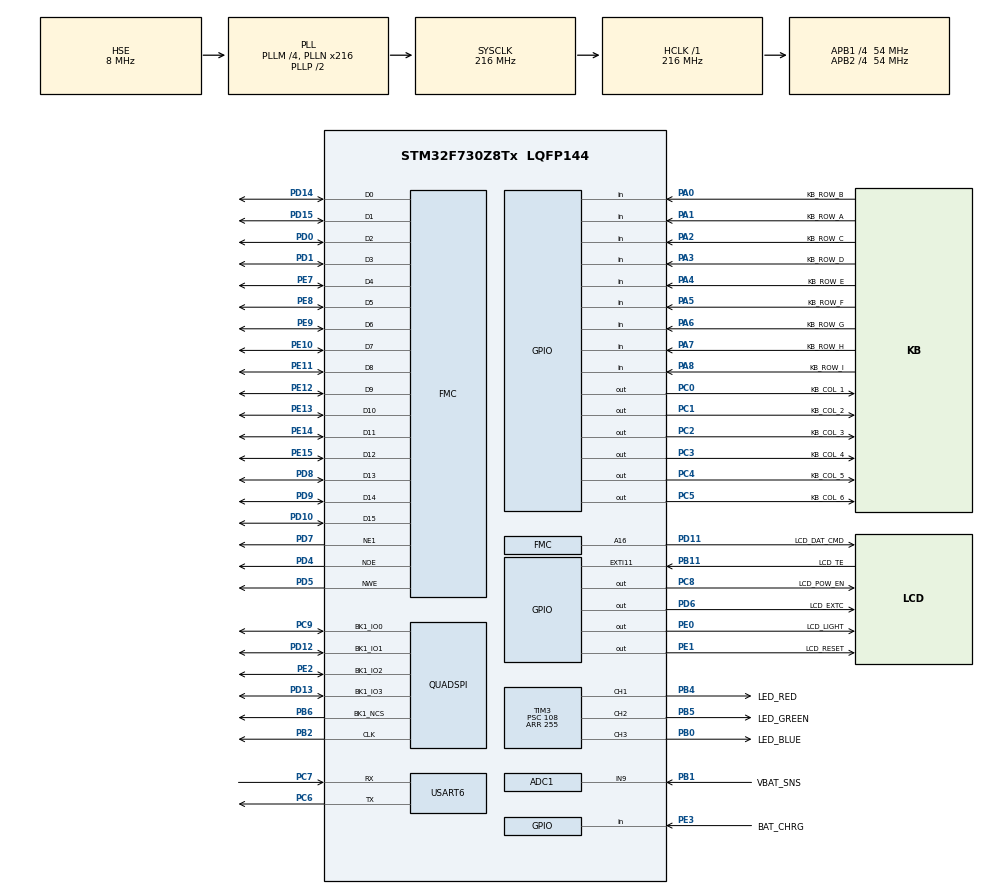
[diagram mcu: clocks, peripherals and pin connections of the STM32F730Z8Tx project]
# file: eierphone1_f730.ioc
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ADC1.Channel-0\#ChannelRegularConversion=ADC_CHANNEL_9
ADC1.NbrOfConversionFlag=1
ADC1.Rank-0\#ChannelRegularConversion=1
ADC1.SamplingTime-0\#ChannelRegularConversion=ADC_SAMPLETIME_3CYCLES
ADC1.master=1
CORTEX_M7.AccessPermission_Spec=MPU_REGION_FULL_ACCESS
CORTEX_M7.CPU_DCache=Disabled
CORTEX_M7.CPU_ICache=Enabled
CORTEX_M7.FlashInterface=TCM_Enabled
CORTEX_M7.PREFETCH_ENABLE=1
CORTEX_M7.default_mode_Activation=1
Dma.MEMTOMEM.0.Direction=DMA_MEMORY_TO_MEMORY
Dma.MEMTOMEM.0.FIFOMode=DMA_FIFOMODE_ENABLE
Dma.MEMTOMEM.0.FIFOThreshold=DMA_FIFO_THRESHOLD_1QUARTERFULL
Dma.MEMTOMEM.0.Instance=DMA2_Stream1
Dma.MEMTOMEM.0.MemBurst=DMA_MBURST_SINGLE
Dma.MEMTOMEM.0.MemDataAlignment=DMA_MDATAALIGN_HALFWORD
Dma.MEMTOMEM.0.MemInc=DMA_MINC_DISABLE
Dma.MEMTOMEM.0.Mode=DMA_NORMAL
Dma.MEMTOMEM.0.PeriphBurst=DMA_PBURST_SINGLE
Dma.MEMTOMEM.0.PeriphDataAlignment=DMA_PDATAALIGN_WORD
Dma.MEMTOMEM.0.PeriphInc=DMA_PINC_ENABLE
Dma.MEMTOMEM.0.Priority=DMA_PRIORITY_HIGH
Dma.Request0=MEMTOMEM
FMC.AddressSetupTime1=2
FMC.BusTurnAroundDuration1=2
FMC.DataSetupTime1=8
FMC.WriteFifo1=FMC_WRITE_FIFO_DISABLE
FMC.WriteFifo2=FMC_WRITE_FIFO_DISABLE
FMC.WriteFifo3=FMC_WRITE_FIFO_DISABLE
FMC.WriteFifo4=FMC_WRITE_FIFO_DISABLE
FREERTOS.INCLUDE_pcTaskGetTaskName=1
FREERTOS.Tasks01=defaultTask,24,128,StartDefaultTask,Default,NULL,Dynamic,NULL,NULL;coreTask,24,512,core,As external,NULL,Dynamic,NULL,NULL
FREERTOS.configCHECK_FOR_STACK_OVERFLOW=2
FREERTOS.configENABLE_FPU=1
FREERTOS.configGENERATE_RUN_TIME_STATS=1
FREERTOS.configRECORD_STACK_HIGH_ADDRESS=1
FREERTOS.configTOTAL_HEAP_SIZE=65536
FREERTOS.configUSE_MALLOC_FAILED_HOOK=1
FREERTOS.configUSE_NEWLIB_REENTRANT=1
Mcu.Family=STM32F7
Mcu.Name=STM32F730Z8Tx
Mcu.Package=LQFP144
NVIC.DMA2_Stream1_IRQn=true\:5\:0\:false\:false\:true\:true\:true\:true\:true
NVIC.EXTI15_10_IRQn=true\:5\:0\:false\:false\:true\:true\:true\:true\:true
NVIC.PriorityGroup=NVIC_PRIORITYGROUP_4
NVIC.QUADSPI_IRQn=true\:5\:0\:false\:false\:true\:true\:true\:true\:true
NVIC.TIM1_UP_TIM10_IRQn=true\:15\:0\:false\:false\:true\:false\:false\:true\:true
NVIC.TIM6_DAC_IRQn=true\:5\:0\:false\:false\:true\:true\:true\:true\:true
NVIC.TimeBase=TIM1_UP_TIM10_IRQn
NVIC.TimeBaseIP=TIM1
PA0-WKUP.GPIO_Label=KB_ROW_B
PA0-WKUP.GPIO_Mode=GPIO_MODE_INPUT
PA0-WKUP.GPIO_PuPd=GPIO_PULLUP
PA0-WKUP.Signal=GPIO_Input
PA1.GPIO_Label=KB_ROW_A
PA1.GPIO_Mode=GPIO_MODE_INPUT
PA1.GPIO_PuPd=GPIO_PULLUP
PA1.Signal=GPIO_Input
PA13.Mode=Serial_Wire
PA13.Signal=SYS_JTMS-SWDIO
PA14.Mode=Serial_Wire
PA14.Signal=SYS_JTCK-SWCLK
PA2.GPIO_Label=KB_ROW_C
PA2.GPIO_Mode=GPIO_MODE_INPUT
PA2.GPIO_PuPd=GPIO_PULLUP
PA2.Signal=GPIO_Input
PA3.GPIO_Label=KB_ROW_D
PA3.GPIO_Mode=GPIO_MODE_INPUT
PA3.GPIO_PuPd=GPIO_PULLUP
PA3.Signal=GPIO_Input
PA4.GPIO_Label=KB_ROW_E
PA4.GPIO_Mode=GPIO_MODE_INPUT
PA4.GPIO_PuPd=GPIO_PULLUP
PA4.Signal=GPIO_Input
PA5.GPIO_Label=KB_ROW_F
PA5.GPIO_Mode=GPIO_MODE_INPUT
PA5.GPIO_PuPd=GPIO_PULLUP
PA5.Signal=GPIO_Input
PA6.GPIO_Label=KB_ROW_G
PA6.GPIO_Mode=GPIO_MODE_INPUT
PA6.GPIO_PuPd=GPIO_PULLUP
PA6.Signal=GPIO_Input
PA7.GPIO_Label=KB_ROW_H
PA7.GPIO_Mode=GPIO_MODE_INPUT
PA7.GPIO_PuPd=GPIO_PULLUP
PA7.Signal=GPIO_Input
PA8.GPIO_Label=KB_ROW_I
PA8.GPIO_Mode=GPIO_MODE_INPUT
PA8.GPIO_PuPd=GPIO_PULLUP
PA8.Signal=GPIO_Input
PB0.GPIO_Label=LED_BLUE
PB0.Signal=S_TIM3_CH3
PB1.GPIO_Label=VBAT_SNS
PB1.Signal=ADCx_IN9
PB11.GPIO_Label=LCD_TE
PB11.GPIO_ModeDefaultEXTI=GPIO_MODE_IT_RISING
PB11.Signal=GPXTI11
PB2.Mode=Single Bank 1
PB2.Signal=QUADSPI_CLK
PB3.Signal=SYS_JTDO-SWO
PB4.GPIO_Label=LED_RED
PB4.Signal=S_TIM3_CH1
PB5.GPIO_Label=LED_GREEN
PB5.Signal=S_TIM3_CH2
PB6.Mode=Single Bank 1
PB6.Signal=QUADSPI_BK1_NCS
PC0.GPIO_Label=KB_COL_1
PC0.GPIO_ModeDefaultOutputPP=GPIO_MODE_OUTPUT_OD
PC0.GPIO_PuPd=GPIO_PULLUP
PC0.GPIO_Speed=GPIO_SPEED_FREQ_LOW
PC0.PinState=GPIO_PIN_SET
PC0.Signal=GPIO_Output
PC1.GPIO_Label=KB_COL_2
PC1.GPIO_ModeDefaultOutputPP=GPIO_MODE_OUTPUT_OD
PC1.GPIO_PuPd=GPIO_PULLUP
PC1.GPIO_Speed=GPIO_SPEED_FREQ_LOW
PC1.PinState=GPIO_PIN_SET
PC1.Signal=GPIO_Output
PC2.GPIO_Label=KB_COL_3
PC2.GPIO_ModeDefaultOutputPP=GPIO_MODE_OUTPUT_OD
PC2.GPIO_PuPd=GPIO_PULLUP
PC2.GPIO_Speed=GPIO_SPEED_FREQ_LOW
PC2.PinState=GPIO_PIN_SET
PC2.Signal=GPIO_Output
PC3.GPIO_Label=KB_COL_4
PC3.GPIO_ModeDefaultOutputPP=GPIO_MODE_OUTPUT_OD
PC3.GPIO_PuPd=GPIO_PULLUP
PC3.GPIO_Speed=GPIO_SPEED_FREQ_LOW
PC3.PinState=GPIO_PIN_SET
PC3.Signal=GPIO_Output
PC4.GPIO_Label=KB_COL_5
PC4.GPIO_ModeDefaultOutputPP=GPIO_MODE_OUTPUT_OD
PC4.GPIO_PuPd=GPIO_PULLUP
PC4.GPIO_Speed=GPIO_SPEED_FREQ_LOW
PC4.PinState=GPIO_PIN_SET
PC4.Signal=GPIO_Output
PC5.GPIO_Label=KB_COL_6
PC5.GPIO_ModeDefaultOutputPP=GPIO_MODE_OUTPUT_OD
PC5.GPIO_PuPd=GPIO_PULLUP
PC5.GPIO_Speed=GPIO_SPEED_FREQ_LOW
PC5.PinState=GPIO_PIN_SET
PC5.Signal=GPIO_Output
PC6.Mode=Asynchronous
PC6.Signal=USART6_TX
PC7.Mode=Asynchronous
PC7.Signal=USART6_RX
PC8.GPIO_Label=LCD_POW_EN
PC8.Signal=GPIO_Output
PC9.GPIO_PuPd=GPIO_PULLUP
PC9.Mode=Single Bank 1
PC9.Signal=QUADSPI_BK1_IO0
PD0.GPIO_Speed_High_Default=GPIO_SPEED_FREQ_HIGH
PD0.Signal=FMC_D2_DA2
PD1.GPIO_Speed_High_Default=GPIO_SPEED_FREQ_HIGH
PD1.Signal=FMC_D3_DA3
PD10.GPIO_Speed_High_Default=GPIO_SPEED_FREQ_HIGH
PD10.Signal=FMC_D15_DA15
PD11.GPIO_Label=LCD_DAT_CMD
PD11.GPIO_Speed_High_Default=GPIO_SPEED_FREQ_HIGH
PD11.Signal=FMC_A16_CLE
PD12.GPIO_PuPd=GPIO_PULLUP
PD12.Mode=Single Bank 1
PD12.Signal=QUADSPI_BK1_IO1
PD13.GPIO_PuPd=GPIO_PULLUP
PD13.Mode=Single Bank 1
PD13.Signal=QUADSPI_BK1_IO3
PD14.GPIO_Speed_High_Default=GPIO_SPEED_FREQ_HIGH
PD14.Signal=FMC_D0_DA0
PD15.GPIO_Speed_High_Default=GPIO_SPEED_FREQ_HIGH
PD15.Signal=FMC_D1_DA1
PD4.GPIO_Speed_High_Default=GPIO_SPEED_FREQ_HIGH
PD4.Signal=FMC_NOE
PD5.GPIO_Speed_High_Default=GPIO_SPEED_FREQ_HIGH
PD5.Signal=FMC_NWE
PD6.GPIO_Label=LCD_EXTC
PD6.Signal=GPIO_Output
PD7.GPIO_Speed_High_Default=GPIO_SPEED_FREQ_HIGH
PD7.Mode=NorPsramChipSelect1_1
PD7.Signal=FMC_NE1
PD8.GPIO_Speed_High_Default=GPIO_SPEED_FREQ_HIGH
PD8.Signal=FMC_D13_DA13
PD9.GPIO_Speed_High_Default=GPIO_SPEED_FREQ_HIGH
PD9.Signal=FMC_D14_DA14
PE0.GPIO_Label=LCD_LIGHT
PE0.GPIO_Speed=GPIO_SPEED_FREQ_HIGH
PE0.Signal=GPIO_Output
PE1.GPIO_Label=LCD_RESET
PE1.Signal=GPIO_Output
PE10.GPIO_Speed_High_Default=GPIO_SPEED_FREQ_HIGH
PE10.Signal=FMC_D7_DA7
PE11.GPIO_Speed_High_Default=GPIO_SPEED_FREQ_HIGH
PE11.Signal=FMC_D8_DA8
PE12.GPIO_Speed_High_Default=GPIO_SPEED_FREQ_HIGH
PE12.Signal=FMC_D9_DA9
PE13.GPIO_Speed_High_Default=GPIO_SPEED_FREQ_HIGH
PE13.Signal=FMC_D10_DA10
PE14.GPIO_Speed_High_Default=GPIO_SPEED_FREQ_HIGH
PE14.Signal=FMC_D11_DA11
PE15.GPIO_Speed_High_Default=GPIO_SPEED_FREQ_HIGH
PE15.Signal=FMC_D12_DA12
PE2.GPIO_PuPd=GPIO_PULLUP
PE2.Mode=Single Bank 1
PE2.Signal=QUADSPI_BK1_IO2
PE3.GPIO_Label=BAT_CHRG
PE3.GPIO_PuPd=GPIO_PULLUP
PE3.Signal=GPIO_Input
PE7.GPIO_Speed_High_Default=GPIO_SPEED_FREQ_HIGH
PE7.Signal=FMC_D4_DA4
PE8.GPIO_Speed_High_Default=GPIO_SPEED_FREQ_HIGH
PE8.Signal=FMC_D5_DA5
PE9.GPIO_Speed_High_Default=GPIO_SPEED_FREQ_HIGH
PE9.Signal=FMC_D6_DA6
PH0-OSC_IN.Mode=HSE-External-Oscillator
PH0-OSC_IN.Signal=RCC_OSC_IN
PH1-OSC_OUT.Mode=HSE-External-Oscillator
PH1-OSC_OUT.Signal=RCC_OSC_OUT
ProjectManager.HeapSize=0x200
ProjectManager.StackSize=0x400
ProjectManager.TargetToolchain=STM32CubeIDE
QUADSPI.ChipSelectHighTime=QSPI_CS_HIGH_TIME_1_CYCLE
QUADSPI.ClockMode=QSPI_CLOCK_MODE_0
QUADSPI.ClockPrescaler=200
QUADSPI.FifoThreshold=1
QUADSPI.FlashSize=23
QUADSPI.SampleShifting=QSPI_SAMPLE_SHIFTING_NONE
RCC.AHBFreq_Value=216000000
RCC.APB1CLKDivider=RCC_HCLK_DIV4
RCC.APB1Freq_Value=54000000
RCC.APB1TimFreq_Value=108000000
RCC.APB2CLKDivider=RCC_HCLK_DIV4
RCC.APB2Freq_Value=54000000
RCC.APB2TimFreq_Value=108000000
RCC.CortexFreq_Value=216000000
RCC.HCLKFreq_Value=216000000
RCC.HSE_VALUE=8000000
RCC.HSI_VALUE=16000000
RCC.LSE_VALUE=32768
RCC.PLL48CLockSelection=RCC_CLK48SOURCE_PLLSAIP
RCC.PLLM=4
RCC.PLLN=216
RCC.PLLSAIP=RCC_PLLSAIP_DIV8
RCC.PLLSourceVirtual=RCC_PLLSOURCE_HSE
RCC.SYSCLKFreq_VALUE=216000000
RCC.SYSCLKSource=RCC_SYSCLKSOURCE_PLLCLK
RCC.USBFreq_Value=48000000
RCC.VCOOutputFreq_Value=432000000
SH.ADCx_IN9.0=ADC1_IN9,IN9
SH.FMC_A16_CLE.0=FMC_A16,A16_1
SH.FMC_D0_DA0.0=FMC_D0,16b-d1
SH.FMC_D10_DA10.0=FMC_D10,16b-d1
SH.FMC_D11_DA11.0=FMC_D11,16b-d1
SH.FMC_D12_DA12.0=FMC_D12,16b-d1
SH.FMC_D13_DA13.0=FMC_D13,16b-d1
SH.FMC_D14_DA14.0=FMC_D14,16b-d1
SH.FMC_D15_DA15.0=FMC_D15,16b-d1
SH.FMC_D1_DA1.0=FMC_D1,16b-d1
SH.FMC_D2_DA2.0=FMC_D2,16b-d1
SH.FMC_D3_DA3.0=FMC_D3,16b-d1
SH.FMC_D4_DA4.0=FMC_D4,16b-d1
SH.FMC_D5_DA5.0=FMC_D5,16b-d1
SH.FMC_D6_DA6.0=FMC_D6,16b-d1
SH.FMC_D7_DA7.0=FMC_D7,16b-d1
SH.FMC_D8_DA8.0=FMC_D8,16b-d1
SH.FMC_D9_DA9.0=FMC_D9,16b-d1
SH.FMC_NOE.0=FMC_NOE,Lcd1
SH.FMC_NWE.0=FMC_NWE,Lcd1
SH.S_TIM3_CH1.0=TIM3_CH1,PWM Generation1 CH1
SH.S_TIM3_CH2.0=TIM3_CH2,PWM Generation2 CH2
SH.S_TIM3_CH3.0=TIM3_CH3,PWM Generation3 CH3
TIM3.AutoReloadPreload=TIM_AUTORELOAD_PRELOAD_ENABLE
TIM3.Channel-PWM\ Generation1\ CH1=TIM_CHANNEL_1
TIM3.Channel-PWM\ Generation2\ CH2=TIM_CHANNEL_2
TIM3.Channel-PWM\ Generation3\ CH3=TIM_CHANNEL_3
TIM3.Period=255
TIM3.Prescaler=108
TIM3.Pulse-PWM\ Generation1\ CH1=0
TIM3.Pulse-PWM\ Generation2\ CH2=0
TIM3.Pulse-PWM\ Generation3\ CH3=0
TIM6.AutoReloadPreload=TIM_AUTORELOAD_PRELOAD_ENABLE
TIM6.Period=20
TIM6.Prescaler=11-1
TIM6.TIM_MasterOutputTrigger=TIM_TRGO_UPDATE
USART6.VirtualMode-Asynchronous=VM_ASYNC
VP_FREERTOS_VS_CMSIS_V2.Mode=CMSIS_V2
VP_SYS_VS_tim1.Mode=TIM1
VP_TIM3_VS_ClockSourceINT.Mode=Internal
VP_TIM6_VS_ClockSourceINT.Mode=Enable_Timer
board=custom

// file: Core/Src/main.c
/* USER CODE BEGIN Header */
/**
 ******************************************************************************
 * @file           : main.c
 * @brief          : Main program body
 ******************************************************************************
 * @attention
 *
 * Copyright (c) 2025 STMicroelectronics.
 * All rights reserved.
 *
 * This software is licensed under terms that can be found in the LICENSE file
 * in the root directory of this software component.
 * If no LICENSE file comes with this software, it is provided AS-IS.
 *
 ******************************************************************************
 */
/* USER CODE END Header */
#include "main.h"
#include "cmsis_os.h"

ADC_HandleTypeDef hadc1;

QSPI_HandleTypeDef hqspi;

TIM_HandleTypeDef htim3;
TIM_HandleTypeDef htim6;

UART_HandleTypeDef huart6;

DMA_HandleTypeDef hdma_memtomem_dma2_stream1;
SRAM_HandleTypeDef hsram1;

/* Definitions for defaultTask */
osThreadId_t defaultTaskHandle;
const osThreadAttr_t defaultTask_attributes = {
  .name = "defaultTask",
  .stack_size = 128 * 4,
  .priority = (osPriority_t) osPriorityNormal,
};
/* Definitions for coreTask */
osThreadId_t coreTaskHandle;
const osThreadAttr_t coreTask_attributes = {
  .name = "coreTask",
  .stack_size = 512 * 4,
  .priority = (osPriority_t) osPriorityNormal,
};

void SystemClock_Config(void);
static void MPU_Config(void);
static void MX_GPIO_Init(void);
static void MX_DMA_Init(void);
static void MX_TIM3_Init(void);
static void MX_QUADSPI_Init(void);
static void MX_ADC1_Init(void);
static void MX_USART6_UART_Init(void);
static void MX_FMC_Init(void);
static void MX_TIM6_Init(void);
void StartDefaultTask(void *argument);
extern void core(void *argument);

int main(void)
{

  /* MPU Configuration--------------------------------------------------------*/
  MPU_Config();

  /* Enable the CPU Cache */

  /* Enable I-Cache---------------------------------------------------------*/
  SCB_EnableICache();

  /* MCU Configuration--------------------------------------------------------*/

  /* Reset of all peripherals, Initializes the Flash interface and the Systick. */
  HAL_Init();

  /* Configure the system clock */
  SystemClock_Config();

  /* Initialize all configured peripherals */
  MX_GPIO_Init();
  MX_DMA_Init();
  MX_TIM3_Init();
  MX_QUADSPI_Init();
  MX_ADC1_Init();
  MX_USART6_UART_Init();
  MX_FMC_Init();
  MX_TIM6_Init();

  /* Init scheduler */
  osKernelInitialize();

  /* Create the thread(s) */
  /* creation of defaultTask */
  defaultTaskHandle = osThreadNew(StartDefaultTask, NULL, &defaultTask_attributes);

  /* creation of coreTask */
  coreTaskHandle = osThreadNew(core, NULL, &coreTask_attributes);

  /* Start scheduler */
  osKernelStart();

  /* We should never get here as control is now taken by the scheduler */

  /* Infinite loop */
	while (1) {

	}
}

void SystemClock_Config(void)
{
  RCC_OscInitTypeDef RCC_OscInitStruct = {0};
  RCC_ClkInitTypeDef RCC_ClkInitStruct = {0};

  /** Configure the main internal regulator output voltage
  */
  __HAL_RCC_PWR_CLK_ENABLE();
  __HAL_PWR_VOLTAGESCALING_CONFIG(PWR_REGULATOR_VOLTAGE_SCALE1);

  /** Initializes the RCC Oscillators according to the specified parameters
  * in the RCC_OscInitTypeDef structure.
  */
  RCC_OscInitStruct.OscillatorType = RCC_OSCILLATORTYPE_HSE;
  RCC_OscInitStruct.HSEState = RCC_HSE_ON;
  RCC_OscInitStruct.PLL.PLLState = RCC_PLL_ON;
  RCC_OscInitStruct.PLL.PLLSource = RCC_PLLSOURCE_HSE;
  RCC_OscInitStruct.PLL.PLLM = 4;
  RCC_OscInitStruct.PLL.PLLN = 216;
  RCC_OscInitStruct.PLL.PLLP = RCC_PLLP_DIV2;
  RCC_OscInitStruct.PLL.PLLQ = 2;
  if (HAL_RCC_OscConfig(&RCC_OscInitStruct) != HAL_OK)
  {
    Error_Handler();
  }

  /** Activate the Over-Drive mode
  */
  if (HAL_PWREx_EnableOverDrive() != HAL_OK)
  {
    Error_Handler();
  }

  /** Initializes the CPU, AHB and APB buses clocks
  */
  RCC_ClkInitStruct.ClockType = RCC_CLOCKTYPE_HCLK|RCC_CLOCKTYPE_SYSCLK
                              |RCC_CLOCKTYPE_PCLK1|RCC_CLOCKTYPE_PCLK2;
  RCC_ClkInitStruct.SYSCLKSource = RCC_SYSCLKSOURCE_PLLCLK;
  RCC_ClkInitStruct.AHBCLKDivider = RCC_SYSCLK_DIV1;
  RCC_ClkInitStruct.APB1CLKDivider = RCC_HCLK_DIV4;
  RCC_ClkInitStruct.APB2CLKDivider = RCC_HCLK_DIV4;

  if (HAL_RCC_ClockConfig(&RCC_ClkInitStruct, FLASH_LATENCY_7) != HAL_OK)
  {
    Error_Handler();
  }
}

static void MX_ADC1_Init(void)
{

  ADC_ChannelConfTypeDef sConfig = {0};

  /** Configure the global features of the ADC (Clock, Resolution, Data Alignment and number of conversion)
  */
  hadc1.Instance = ADC1;
  hadc1.Init.ClockPrescaler = ADC_CLOCK_SYNC_PCLK_DIV2;
  hadc1.Init.Resolution = ADC_RESOLUTION_12B;
  hadc1.Init.ScanConvMode = ADC_SCAN_DISABLE;
  hadc1.Init.ContinuousConvMode = DISABLE;
  hadc1.Init.DiscontinuousConvMode = DISABLE;
  hadc1.Init.ExternalTrigConvEdge = ADC_EXTERNALTRIGCONVEDGE_NONE;
  hadc1.Init.ExternalTrigConv = ADC_SOFTWARE_START;
  hadc1.Init.DataAlign = ADC_DATAALIGN_RIGHT;
  hadc1.Init.NbrOfConversion = 1;
  hadc1.Init.DMAContinuousRequests = DISABLE;
  hadc1.Init.EOCSelection = ADC_EOC_SINGLE_CONV;
  if (HAL_ADC_Init(&hadc1) != HAL_OK)
  {
    Error_Handler();
  }

  /** Configure for the selected ADC regular channel its corresponding rank in the sequencer and its sample time.
  */
  sConfig.Channel = ADC_CHANNEL_9;
  sConfig.Rank = ADC_REGULAR_RANK_1;
  sConfig.SamplingTime = ADC_SAMPLETIME_3CYCLES;
  if (HAL_ADC_ConfigChannel(&hadc1, &sConfig) != HAL_OK)
  {
    Error_Handler();
  }

}

static void MX_QUADSPI_Init(void)
{

  /* QUADSPI parameter configuration*/
  hqspi.Instance = QUADSPI;
  hqspi.Init.ClockPrescaler = 200;
  hqspi.Init.FifoThreshold = 1;
  hqspi.Init.SampleShifting = QSPI_SAMPLE_SHIFTING_NONE;
  hqspi.Init.FlashSize = 23;
  hqspi.Init.ChipSelectHighTime = QSPI_CS_HIGH_TIME_1_CYCLE;
  hqspi.Init.ClockMode = QSPI_CLOCK_MODE_0;
  hqspi.Init.FlashID = QSPI_FLASH_ID_1;
  hqspi.Init.DualFlash = QSPI_DUALFLASH_DISABLE;
  if (HAL_QSPI_Init(&hqspi) != HAL_OK)
  {
    Error_Handler();
  }

}

static void MX_TIM3_Init(void)
{

  TIM_ClockConfigTypeDef sClockSourceConfig = {0};
  TIM_MasterConfigTypeDef sMasterConfig = {0};
  TIM_OC_InitTypeDef sConfigOC = {0};

  htim3.Instance = TIM3;
  htim3.Init.Prescaler = 108;
  htim3.Init.CounterMode = TIM_COUNTERMODE_UP;
  htim3.Init.Period = 255;
  htim3.Init.ClockDivision = TIM_CLOCKDIVISION_DIV1;
  htim3.Init.AutoReloadPreload = TIM_AUTORELOAD_PRELOAD_ENABLE;
  if (HAL_TIM_Base_Init(&htim3) != HAL_OK)
  {
    Error_Handler();
  }
  sClockSourceConfig.ClockSource = TIM_CLOCKSOURCE_INTERNAL;
  if (HAL_TIM_ConfigClockSource(&htim3, &sClockSourceConfig) != HAL_OK)
  {
    Error_Handler();
  }
  if (HAL_TIM_PWM_Init(&htim3) != HAL_OK)
  {
    Error_Handler();
  }
  sMasterConfig.MasterOutputTrigger = TIM_TRGO_RESET;
  sMasterConfig.MasterSlaveMode = TIM_MASTERSLAVEMODE_DISABLE;
  if (HAL_TIMEx_MasterConfigSynchronization(&htim3, &sMasterConfig) != HAL_OK)
  {
    Error_Handler();
  }
  sConfigOC.OCMode = TIM_OCMODE_PWM1;
  sConfigOC.Pulse = 0;
  sConfigOC.OCPolarity = TIM_OCPOLARITY_HIGH;
  sConfigOC.OCFastMode = TIM_OCFAST_DISABLE;
  if (HAL_TIM_PWM_ConfigChannel(&htim3, &sConfigOC, TIM_CHANNEL_1) != HAL_OK)
  {
    Error_Handler();
  }
  if (HAL_TIM_PWM_ConfigChannel(&htim3, &sConfigOC, TIM_CHANNEL_2) != HAL_OK)
  {
    Error_Handler();
  }
  if (HAL_TIM_PWM_ConfigChannel(&htim3, &sConfigOC, TIM_CHANNEL_3) != HAL_OK)
  {
    Error_Handler();
  }
  HAL_TIM_MspPostInit(&htim3);

}

static void MX_TIM6_Init(void)
{

  TIM_MasterConfigTypeDef sMasterConfig = {0};

  htim6.Instance = TIM6;
  htim6.Init.Prescaler = 11-1;
  htim6.Init.CounterMode = TIM_COUNTERMODE_UP;
  htim6.Init.Period = 20;
  htim6.Init.AutoReloadPreload = TIM_AUTORELOAD_PRELOAD_ENABLE;
  if (HAL_TIM_Base_Init(&htim6) != HAL_OK)
  {
    Error_Handler();
  }
  sMasterConfig.MasterOutputTrigger = TIM_TRGO_UPDATE;
  sMasterConfig.MasterSlaveMode = TIM_MASTERSLAVEMODE_DISABLE;
  if (HAL_TIMEx_MasterConfigSynchronization(&htim6, &sMasterConfig) != HAL_OK)
  {
    Error_Handler();
  }

}

static void MX_USART6_UART_Init(void)
{

  huart6.Instance = USART6;
  huart6.Init.BaudRate = 115200;
  huart6.Init.WordLength = UART_WORDLENGTH_8B;
  huart6.Init.StopBits = UART_STOPBITS_1;
  huart6.Init.Parity = UART_PARITY_NONE;
  huart6.Init.Mode = UART_MODE_TX_RX;
  huart6.Init.HwFlowCtl = UART_HWCONTROL_NONE;
  huart6.Init.OverSampling = UART_OVERSAMPLING_16;
  huart6.Init.OneBitSampling = UART_ONE_BIT_SAMPLE_DISABLE;
  huart6.AdvancedInit.AdvFeatureInit = UART_ADVFEATURE_NO_INIT;
  if (HAL_UART_Init(&huart6) != HAL_OK)
  {
    Error_Handler();
  }

}

static void MX_DMA_Init(void)
{

  /* DMA controller clock enable */
  __HAL_RCC_DMA2_CLK_ENABLE();

  /* Configure DMA request hdma_memtomem_dma2_stream1 on DMA2_Stream1 */
  hdma_memtomem_dma2_stream1.Instance = DMA2_Stream1;
  hdma_memtomem_dma2_stream1.Init.Channel = DMA_CHANNEL_0;
  hdma_memtomem_dma2_stream1.Init.Direction = DMA_MEMORY_TO_MEMORY;
  hdma_memtomem_dma2_stream1.Init.PeriphInc = DMA_PINC_ENABLE;
  hdma_memtomem_dma2_stream1.Init.MemInc = DMA_MINC_DISABLE;
  hdma_memtomem_dma2_stream1.Init.PeriphDataAlignment = DMA_PDATAALIGN_WORD;
  hdma_memtomem_dma2_stream1.Init.MemDataAlignment = DMA_MDATAALIGN_HALFWORD;
  hdma_memtomem_dma2_stream1.Init.Mode = DMA_NORMAL;
  hdma_memtomem_dma2_stream1.Init.Priority = DMA_PRIORITY_HIGH;
  hdma_memtomem_dma2_stream1.Init.FIFOMode = DMA_FIFOMODE_ENABLE;
  hdma_memtomem_dma2_stream1.Init.FIFOThreshold = DMA_FIFO_THRESHOLD_1QUARTERFULL;
  hdma_memtomem_dma2_stream1.Init.MemBurst = DMA_MBURST_SINGLE;
  hdma_memtomem_dma2_stream1.Init.PeriphBurst = DMA_PBURST_SINGLE;
  if (HAL_DMA_Init(&hdma_memtomem_dma2_stream1) != HAL_OK)
  {
    Error_Handler( );
  }

  /* DMA interrupt init */
  /* DMA2_Stream1_IRQn interrupt configuration */
  HAL_NVIC_SetPriority(DMA2_Stream1_IRQn, 5, 0);
  HAL_NVIC_EnableIRQ(DMA2_Stream1_IRQn);

}

/* FMC initialization function */
static void MX_FMC_Init(void)
{

  FMC_NORSRAM_TimingTypeDef Timing = {0};

  /** Perform the SRAM1 memory initialization sequence
  */
  hsram1.Instance = FMC_NORSRAM_DEVICE;
  hsram1.Extended = FMC_NORSRAM_EXTENDED_DEVICE;
  /* hsram1.Init */
  hsram1.Init.NSBank = FMC_NORSRAM_BANK1;
  hsram1.Init.DataAddressMux = FMC_DATA_ADDRESS_MUX_DISABLE;
  hsram1.Init.MemoryType = FMC_MEMORY_TYPE_SRAM;
  hsram1.Init.MemoryDataWidth = FMC_NORSRAM_MEM_BUS_WIDTH_16;
  hsram1.Init.BurstAccessMode = FMC_BURST_ACCESS_MODE_DISABLE;
  hsram1.Init.WaitSignalPolarity = FMC_WAIT_SIGNAL_POLARITY_LOW;
  hsram1.Init.WaitSignalActive = FMC_WAIT_TIMING_BEFORE_WS;
  hsram1.Init.WriteOperation = FMC_WRITE_OPERATION_ENABLE;
  hsram1.Init.WaitSignal = FMC_WAIT_SIGNAL_DISABLE;
  hsram1.Init.ExtendedMode = FMC_EXTENDED_MODE_DISABLE;
  hsram1.Init.AsynchronousWait = FMC_ASYNCHRONOUS_WAIT_DISABLE;
  hsram1.Init.WriteBurst = FMC_WRITE_BURST_DISABLE;
  hsram1.Init.ContinuousClock = FMC_CONTINUOUS_CLOCK_SYNC_ONLY;
  hsram1.Init.WriteFifo = FMC_WRITE_FIFO_DISABLE;
  hsram1.Init.PageSize = FMC_PAGE_SIZE_NONE;
  /* Timing */
  Timing.AddressSetupTime = 2;
  Timing.AddressHoldTime = 15;
  Timing.DataSetupTime = 8;
  Timing.BusTurnAroundDuration = 2;
  Timing.CLKDivision = 16;
  Timing.DataLatency = 17;
  Timing.AccessMode = FMC_ACCESS_MODE_A;
  /* ExtTiming */

  if (HAL_SRAM_Init(&hsram1, &Timing, NULL) != HAL_OK)
  {
    Error_Handler( );
  }

}

static void MX_GPIO_Init(void)
{
  GPIO_InitTypeDef GPIO_InitStruct = {0};

  /* GPIO Ports Clock Enable */
  __HAL_RCC_GPIOE_CLK_ENABLE();
  __HAL_RCC_GPIOH_CLK_ENABLE();
  __HAL_RCC_GPIOC_CLK_ENABLE();
  __HAL_RCC_GPIOA_CLK_ENABLE();
  __HAL_RCC_GPIOB_CLK_ENABLE();
  __HAL_RCC_GPIOD_CLK_ENABLE();

  /*Configure GPIO pin Output Level */
  HAL_GPIO_WritePin(GPIOC, KB_COL_1_Pin|KB_COL_2_Pin|KB_COL_3_Pin|KB_COL_4_Pin
                          |KB_COL_5_Pin|KB_COL_6_Pin, GPIO_PIN_SET);

  /*Configure GPIO pin Output Level */
  HAL_GPIO_WritePin(LCD_POW_EN_GPIO_Port, LCD_POW_EN_Pin, GPIO_PIN_RESET);

  /*Configure GPIO pin Output Level */
  HAL_GPIO_WritePin(LCD_EXTC_GPIO_Port, LCD_EXTC_Pin, GPIO_PIN_RESET);

  /*Configure GPIO pin Output Level */
  HAL_GPIO_WritePin(GPIOE, LCD_LIGHT_Pin|LCD_RESET_Pin, GPIO_PIN_RESET);

  /*Configure GPIO pin : BAT_CHRG_Pin */
  GPIO_InitStruct.Pin = BAT_CHRG_Pin;
  GPIO_InitStruct.Mode = GPIO_MODE_INPUT;
  GPIO_InitStruct.Pull = GPIO_PULLUP;
  HAL_GPIO_Init(BAT_CHRG_GPIO_Port, &GPIO_InitStruct);

  /*Configure GPIO pins : KB_COL_1_Pin KB_COL_2_Pin KB_COL_3_Pin KB_COL_4_Pin
                           KB_COL_5_Pin KB_COL_6_Pin */
  GPIO_InitStruct.Pin = KB_COL_1_Pin|KB_COL_2_Pin|KB_COL_3_Pin|KB_COL_4_Pin
                          |KB_COL_5_Pin|KB_COL_6_Pin;
  GPIO_InitStruct.Mode = GPIO_MODE_OUTPUT_OD;
  GPIO_InitStruct.Pull = GPIO_PULLUP;
  GPIO_InitStruct.Speed = GPIO_SPEED_FREQ_LOW;
  HAL_GPIO_Init(GPIOC, &GPIO_InitStruct);

  /*Configure GPIO pins : KB_ROW_B_Pin KB_ROW_A_Pin KB_ROW_C_Pin KB_ROW_D_Pin
                           KB_ROW_E_Pin KB_ROW_F_Pin KB_ROW_G_Pin KB_ROW_H_Pin
                           KB_ROW_I_Pin */
  GPIO_InitStruct.Pin = KB_ROW_B_Pin|KB_ROW_A_Pin|KB_ROW_C_Pin|KB_ROW_D_Pin
                          |KB_ROW_E_Pin|KB_ROW_F_Pin|KB_ROW_G_Pin|KB_ROW_H_Pin
                          |KB_ROW_I_Pin;
  GPIO_InitStruct.Mode = GPIO_MODE_INPUT;
  GPIO_InitStruct.Pull = GPIO_PULLUP;
  HAL_GPIO_Init(GPIOA, &GPIO_InitStruct);

  /*Configure GPIO pin : LCD_TE_Pin */
  GPIO_InitStruct.Pin = LCD_TE_Pin;
  GPIO_InitStruct.Mode = GPIO_MODE_IT_RISING;
  GPIO_InitStruct.Pull = GPIO_NOPULL;
  HAL_GPIO_Init(LCD_TE_GPIO_Port, &GPIO_InitStruct);

  /*Configure GPIO pin : LCD_POW_EN_Pin */
  GPIO_InitStruct.Pin = LCD_POW_EN_Pin;
  GPIO_InitStruct.Mode = GPIO_MODE_OUTPUT_PP;
  GPIO_InitStruct.Pull = GPIO_NOPULL;
  GPIO_InitStruct.Speed = GPIO_SPEED_FREQ_LOW;
  HAL_GPIO_Init(LCD_POW_EN_GPIO_Port, &GPIO_InitStruct);

  /*Configure GPIO pin : LCD_EXTC_Pin */
  GPIO_InitStruct.Pin = LCD_EXTC_Pin;
  GPIO_InitStruct.Mode = GPIO_MODE_OUTPUT_PP;
  GPIO_InitStruct.Pull = GPIO_NOPULL;
  GPIO_InitStruct.Speed = GPIO_SPEED_FREQ_LOW;
  HAL_GPIO_Init(LCD_EXTC_GPIO_Port, &GPIO_InitStruct);

  /*Configure GPIO pin : LCD_LIGHT_Pin */
  GPIO_InitStruct.Pin = LCD_LIGHT_Pin;
  GPIO_InitStruct.Mode = GPIO_MODE_OUTPUT_PP;
  GPIO_InitStruct.Pull = GPIO_NOPULL;
  GPIO_InitStruct.Speed = GPIO_SPEED_FREQ_HIGH;
  HAL_GPIO_Init(LCD_LIGHT_GPIO_Port, &GPIO_InitStruct);

  /*Configure GPIO pin : LCD_RESET_Pin */
  GPIO_InitStruct.Pin = LCD_RESET_Pin;
  GPIO_InitStruct.Mode = GPIO_MODE_OUTPUT_PP;
  GPIO_InitStruct.Pull = GPIO_NOPULL;
  GPIO_InitStruct.Speed = GPIO_SPEED_FREQ_LOW;
  HAL_GPIO_Init(LCD_RESET_GPIO_Port, &GPIO_InitStruct);

  /* EXTI interrupt init*/
  HAL_NVIC_SetPriority(EXTI15_10_IRQn, 5, 0);
  HAL_NVIC_EnableIRQ(EXTI15_10_IRQn);

}

/* USER CODE BEGIN 4 */
void HAL_GPIO_EXTI_Callback(uint16_t GPIO_Pin) {
	if (GPIO_Pin == LCD_TE_Pin) {
		hw_screen_stream_framebuffer();
	}
}
/* USER CODE END 4 */

void StartDefaultTask(void *argument)
{
  /* USER CODE BEGIN 5 */
	vTaskDelete(NULL);
  /* USER CODE END 5 */
}

 /* MPU Configuration */

void MPU_Config(void)
{
  MPU_Region_InitTypeDef MPU_InitStruct = {0};

  /* Disables the MPU */
  HAL_MPU_Disable();

  /** Initializes and configures the Region and the memory to be protected
  */
  MPU_InitStruct.Enable = MPU_REGION_ENABLE;
  MPU_InitStruct.Number = MPU_REGION_NUMBER0;
  MPU_InitStruct.BaseAddress = 0x0;
  MPU_InitStruct.Size = MPU_REGION_SIZE_4GB;
  MPU_InitStruct.SubRegionDisable = 0x87;
  MPU_InitStruct.TypeExtField = MPU_TEX_LEVEL0;
  MPU_InitStruct.AccessPermission = MPU_REGION_FULL_ACCESS;
  MPU_InitStruct.DisableExec = MPU_INSTRUCTION_ACCESS_DISABLE;
  MPU_InitStruct.IsShareable = MPU_ACCESS_SHAREABLE;
  MPU_InitStruct.IsCacheable = MPU_ACCESS_NOT_CACHEABLE;
  MPU_InitStruct.IsBufferable = MPU_ACCESS_NOT_BUFFERABLE;

  HAL_MPU_ConfigRegion(&MPU_InitStruct);
  /* Enables the MPU */
  HAL_MPU_Enable(MPU_PRIVILEGED_DEFAULT);

}

void HAL_TIM_PeriodElapsedCallback(TIM_HandleTypeDef *htim)
{
  if (htim->Instance == TIM1) {
    HAL_IncTick();
  }
  /* USER CODE BEGIN Callback 1 */
	if (htim->Instance == TIM6) {
		hw_screen_led_timer_callback();
	}
  /* USER CODE END Callback 1 */
}

void Error_Handler(void)
{
	__disable_irq();
	while (1) {
	}
}

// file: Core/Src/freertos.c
/* USER CODE BEGIN Header */
/**
  ******************************************************************************
  * File Name          : freertos.c
  * Description        : Code for freertos applications
  ******************************************************************************
  * @attention
  *
  * Copyright (c) 2025 STMicroelectronics.
  * All rights reserved.
  *
  * This software is licensed under terms that can be found in the LICENSE file
  * in the root directory of this software component.
  * If no LICENSE file comes with this software, it is provided AS-IS.
  *
  ******************************************************************************
  */
/* USER CODE END Header */

#include "FreeRTOS.h"
#include "task.h"
#include "main.h"

/* Hook prototypes */
void configureTimerForRunTimeStats(void);
unsigned long getRunTimeCounterValue(void);
void vApplicationStackOverflowHook(xTaskHandle xTask, signed char *pcTaskName);
void vApplicationMallocFailedHook(void);

/* USER CODE BEGIN 1 */
/* Functions needed when configGENERATE_RUN_TIME_STATS is on */
__weak void configureTimerForRunTimeStats(void)
{

}

__weak unsigned long getRunTimeCounterValue(void)
{
return 0;
}
/* USER CODE END 1 */

/* USER CODE BEGIN 4 */
void vApplicationStackOverflowHook(xTaskHandle xTask, signed char *pcTaskName)
{
   /* Run time stack overflow checking is performed if
   configCHECK_FOR_STACK_OVERFLOW is defined to 1 or 2. This hook function is
   called if a stack overflow is detected. */
}
/* USER CODE END 4 */

/* USER CODE BEGIN 5 */
void vApplicationMallocFailedHook(void)
{
   /* vApplicationMallocFailedHook() will only be called if
   configUSE_MALLOC_FAILED_HOOK is set to 1 in FreeRTOSConfig.h. It is a hook
   function that will get called if a call to pvPortMalloc() fails.
   pvPortMalloc() is called internally by the kernel whenever a task, queue,
   timer or semaphore is created. It is also called by various parts of the
   demo application. If heap_1.c or heap_2.c are used, then the size of the
   heap available to pvPortMalloc() is defined by configTOTAL_HEAP_SIZE in
   FreeRTOSConfig.h, and the xPortGetFreeHeapSize() API function can be used
   to query the size of free heap space that remains (although it does not
   provide information on how the remaining heap might be fragmented). */
}
/* USER CODE END 5 */
